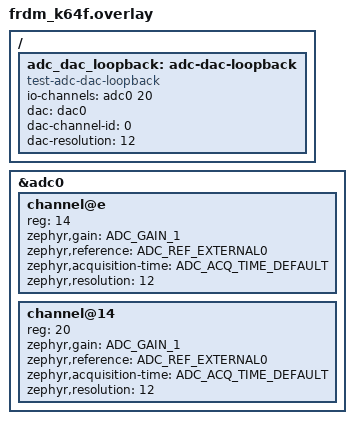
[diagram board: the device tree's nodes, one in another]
/*
 * SPDX-License-Identifier: Apache-2.0
 *
 * Copyright (c) 2023 Benjamin Björnsson <benjamin.bjornsson@gmail.com>
 */

&adc0 {
	#address-cells = <1>;
	#size-cells = <0>;
	status = "okay";

	channel@e {
		reg = <14>;
		zephyr,gain = "ADC_GAIN_1";
		zephyr,reference = "ADC_REF_EXTERNAL0";
		zephyr,acquisition-time = <ADC_ACQ_TIME_DEFAULT>;
		zephyr,resolution = <12>;
	};

	channel@14 {
		reg = <20>;
		zephyr,gain = "ADC_GAIN_1";
		zephyr,reference = "ADC_REF_EXTERNAL0";
		zephyr,acquisition-time = <ADC_ACQ_TIME_DEFAULT>;
		zephyr,resolution = <12>;
	};
};

/ {
	adc_dac_loopback: adc-dac-loopback {
		compatible = "test-adc-dac-loopback";
		io-channels = <&adc0 20>;
		dac = <&dac0>;
		dac-channel-id = <0>;
		dac-resolution = <12>;
	};
};
